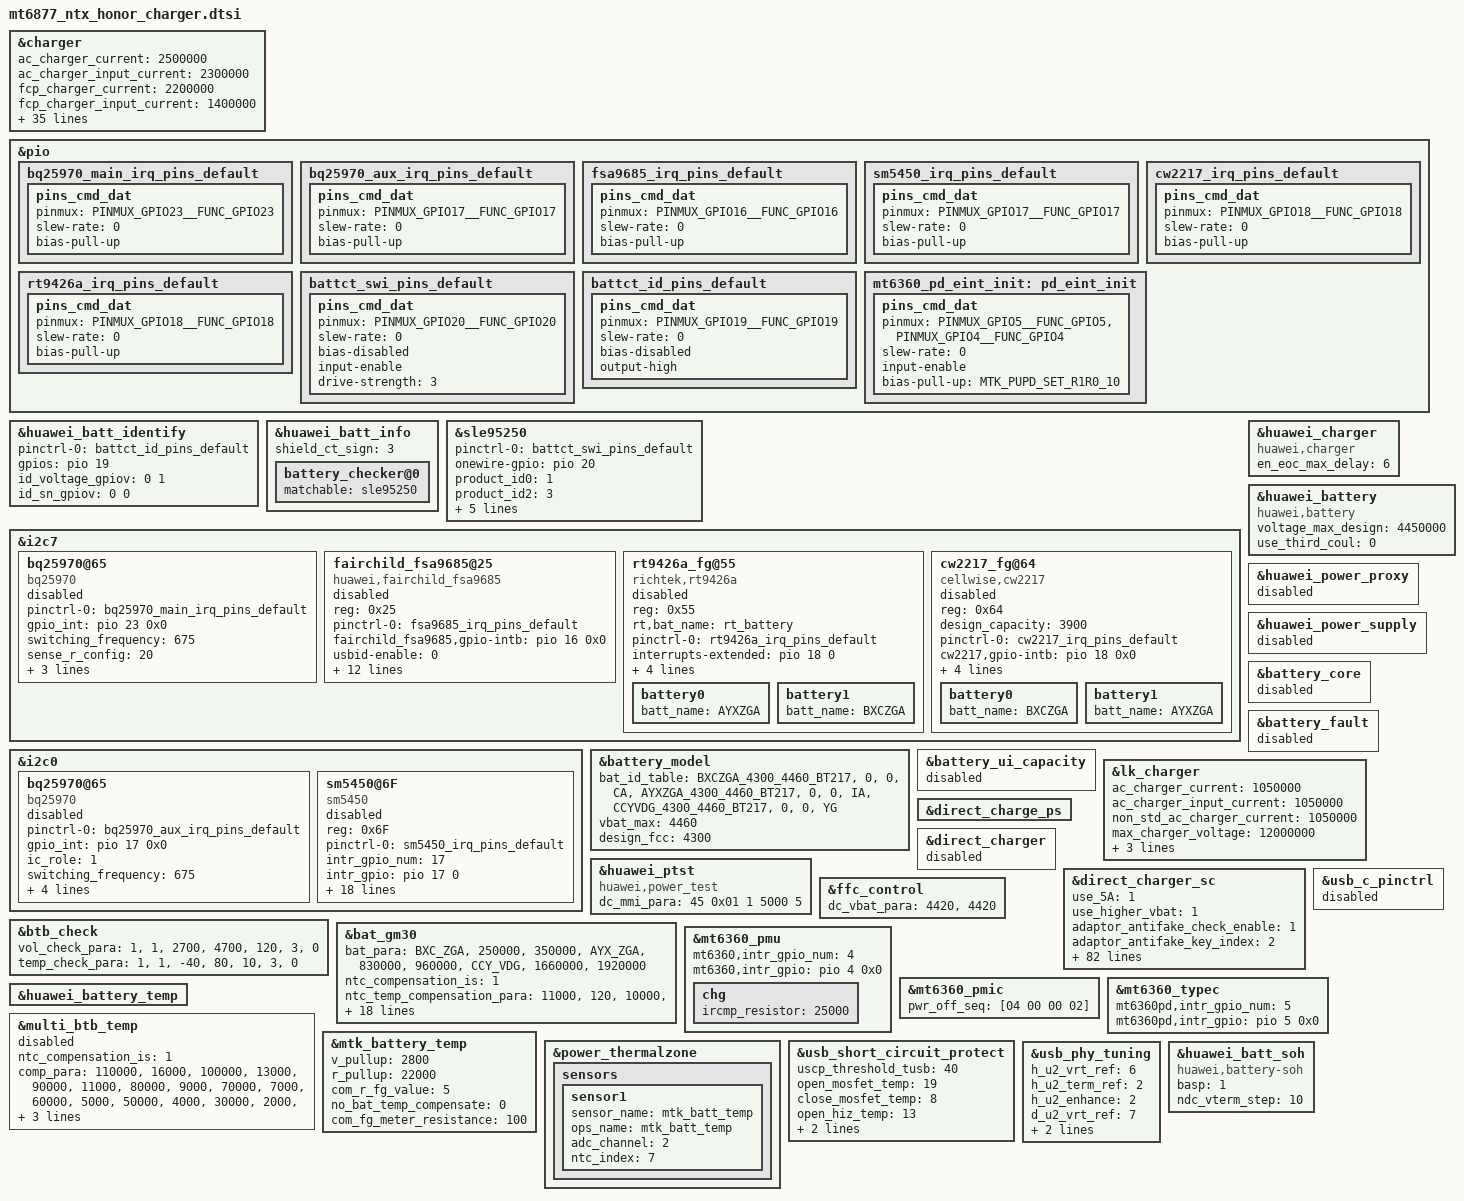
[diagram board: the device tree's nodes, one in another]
&charger {
	ac_charger_current = <2500000>;
	ac_charger_input_current = <2300000>;
	fcp_charger_current = <2200000>;
	fcp_charger_input_current = <1400000>;
	non_std_ac_charger_current = <1200000>;
	pd_vbus_upper_bound = <9000000>;
	max_charger_voltage = <12000000>;
	bc12_charger = <0>; /* mt6360 do bc12 */
	dpm_enable;
	battery_cv = <4450000>;
	sdp_battery_cv = <4430000>;
	iterm = <150000>;
	vbus_max_limit = <11500>;
	jeita_temp_above_t4_cv = <4100000>;
	jeita_temp_t3_to_t4_cv = <4100000>;
	jeita_temp_t2_to_t3_cv = <4450000>;
	jeita_temp_t1_to_t2_cv = <4430000>;
	jeita_temp_t0_to_t1_cv = <4430000>;
	jeita_temp_below_t0_cv = <4100000>;
	jeita_temp_t3_to_t4_cur = <1400000>;
	jeita_temp_t2_to_t3_cur = <2800000>;
	jeita_temp_t1_to_t2_cur = <1200000>;
	jeita_temp_t0_to_t1_cur = <420000>;
	dynamic_iterm_en;
	jeita_temp_t0_to_t1_iterm = <150000>;
	jeita_temp_t1_to_t2_iterm = <150000>;
	jeita_temp_t2_to_t3_iterm = <500000>;
	jeita_temp_t3_to_t4_iterm = <150000>;
	/* mode jeita param */
	support_over_volt = <1>;
	jeita_normal_temp_iterm = <500000>;
	jeita_normal_temp_cv = <4450000>;
	jeita_iin_therm_iterm = <150000>;
	jeita_iin_therm_cv = <4430000>;
	sdp_jeita_temp_t2_to_t3_cv = <4430000>;
	sdp_jeita_temp_t2_to_t3_iterm = <150000>;
	vdpm_buf_limit = <100>;
	vdpm_para =
			"-32767", "4000", "4300", "50",
			"4000", "4200", "4500", "50",
			"4200", "32767", "4600", "50";
	charge_full_design = <4300000>;
};

&pio {
	bq25970_main_irq_pins_default: bq25970_main_irq_pins_default {
		pins_cmd_dat {
			pinmux = <PINMUX_GPIO23__FUNC_GPIO23>;
			slew-rate = <0>;
			bias-pull-up;
		};
	};
	bq25970_aux_irq_pins_default: bq25970_aux_irq_pins_default {
		pins_cmd_dat {
			pinmux = <PINMUX_GPIO17__FUNC_GPIO17>;
			slew-rate = <0>;
			bias-pull-up;
		};
	};
	fsa9685_irq_pins_default: fsa9685_irq_pins_default {
		pins_cmd_dat {
			pinmux = <PINMUX_GPIO16__FUNC_GPIO16>;
			slew-rate = <0>;
			bias-pull-up;
		};
	};

	sm5450_irq_pins_default: sm5450_irq_pins_default {
		pins_cmd_dat {
			pinmux = <PINMUX_GPIO17__FUNC_GPIO17>;
			slew-rate = <0>;
			bias-pull-up;
		};
	};
	cw2217_irq_pins_default: cw2217_irq_pins_default {
		pins_cmd_dat {
			pinmux = <PINMUX_GPIO18__FUNC_GPIO18>;
			slew-rate = <0>;
			bias-pull-up;
		};
	};
	rt9426a_irq_pins_default: rt9426a_irq_pins_default {
		pins_cmd_dat {
			pinmux = <PINMUX_GPIO18__FUNC_GPIO18>;
			slew-rate = <0>;
			bias-pull-up;
		};
	};
        battct_swi_pins_default: battct_swi_pins_default {
                pins_cmd_dat {
                        pinmux = <PINMUX_GPIO20__FUNC_GPIO20>;
                        slew-rate = <0>;
                        bias-disabled;
                        input-enable;
                        drive-strength = <3>;
                };
        };
        battct_id_pins_default: battct_id_pins_default {
                pins_cmd_dat {
                        pinmux = <PINMUX_GPIO19__FUNC_GPIO19>;
                        slew-rate = <0>;
                        bias-disabled;
                        output-high;
                };
        };
};

&huawei_batt_identify {
        pinctrl-names = "default";
        pinctrl-0 = <&battct_id_pins_default>;
        gpios = <&pio 19 0x0>;
        id_voltage_gpiov = <0 1>;
        id_sn_gpiov = <0 0>;
        status = "ok";
};

&huawei_batt_info {
        status = "ok";
        shield_ct_sign = <3>;
        battery_checker@0 {
                matchable = <&sle95250>;
                status = "ok";
        };
};

&sle95250 {
        pinctrl-names = "default";
        pinctrl-0 = <&battct_swi_pins_default>;
        onewire-gpio = <&pio 20 0x0>;
        product_id0 = <1>;
        product_id2 = <3>;
        gpio_sn_mode_val = <0>;
        dip_check = <0>;
        gpio_swi = <20>;
        gpio_id_mode = <19>;
        gpio_swi_drv = <3>;
        status = "ok";
};

&i2c7 {
	bq25970@65 {
		compatible = "bq25970";
		pinctrl-names = "default";
		pinctrl-0 = <&bq25970_main_irq_pins_default>;
		gpio_int = <&pio 23 0x0>;
		switching_frequency = <675>;
		sense_r_config = <20>;
		sense_r_actual = <10>;
		reg = <0x65>;
		ibus_ocp_th = <4250>;
		status = "disabled";
	};

	fairchild_fsa9685@25 {
		compatible = "huawei,fairchild_fsa9685";
		reg = <0x25>;
		pinctrl-names = "default";
		pinctrl-0 = <&fsa9685_irq_pins_default>;
		fairchild_fsa9685,gpio-intb = <&pio 16 0x0>;
		usbid-enable = <0>;
		fcp_support = <1>;
		scp_support = <1>;
		mhl_detect_disable = <1>;
		power_by_5v = <1>;
		close_bc12 = <1>;
		need_other_bc12 = <0>;
		ignore_force_ac = <1>;
		/* for rt8979 */
		interrupt-names = "vbus_change", "device_change", "detach",
			"attach";
		/* auto_switch; */
		scp;
		dcd;
		dcd_timeout = <600>;  /* ms */
		intb_watchdog = <1000>;  /* ms */
		ovp_sel = <14500000>;  /* uV */
		status = "disabled";
	};

	rt9426a_fg@55 {
		compatible = "richtek,rt9426a";
		reg = <0x55>;
		status = "disabled";
		rt,bat_name = "rt_battery";
		pinctrl-names = "default";
		pinctrl-0 = <&rt9426a_irq_pins_default>;
		interrupts-extended = <&pio 18 0>;
		ntc_compensation_is = <1>;
		ntc_temp_compensation_para =
			"11000", "110",
			"10000", "100",
			"9000", "80",
			"8000", "60",
			"7000", "50",
			"6000", "40",
			"5000", "30",
			"3000", "20",
			"2000", "10";
		battery0{
			batt_name = "AYXZGA";
			#include "rt9426a_AYXZGA_4300mah_4V45_BT217.dtsi"
		};
		battery1{
			batt_name = "BXCZGA";
			#include "rt9426a_BXCZGA_4300mah_4V45_BT217.dtsi"
		};
	};
	cw2217_fg@64 {
		reg = <0x64>;
		compatible = "cellwise,cw2217";
		status = "disabled";
		design_capacity = <3900>;
		pinctrl-names = "default";
		pinctrl-0 = <&cw2217_irq_pins_default>;
		cw2217,gpio-intb = <&pio 18 0x0>;
		ntc_compensation_is = <1>;
		ntc_temp_compensation_para =
			"11000", "140",
			"10000", "120",
			"9000", "100",
			"8000", "80",
			"7000", "60",
			"6000", "50",
			"5000", "40",
			"3000", "20",
			"2000", "10";
		battery0{
			batt_name = "BXCZGA";
			#include "CW_BXCZGA_4460_4300mah_BT217.dtsi"
		};
		battery1{
			batt_name = "AYXZGA";
			#include "CW_AYXZGA_4460_4300mah_BT217.dtsi"
		};
	};
};
&i2c0 {
	bq25970@65 {
		compatible = "bq25970";
		pinctrl-names = "default";
		pinctrl-0 = <&bq25970_aux_irq_pins_default>;
		gpio_int = <&pio 17 0x0>;
		ic_role = <1>;
		switching_frequency = <675>;
		sense_r_config = <20>;
		sense_r_actual = <10>;
		reg = <0x65>;
		ibus_ocp_th = <4250>;
		status = "disabled";
	};

	sm5450@6F{
		compatible = "sm5450";
		reg = <0x6F>;
		pinctrl-names = "default";
		pinctrl-0 = <&sm5450_irq_pins_default>;
		intr_gpio_num = <17>;
		intr_gpio = <&pio 17 0>;
		ic_role = <1>;
		support_unbalanced_current_sc = <0>;
		adc_channel_vbat_sys = <14>;
		fcp_support = <1>;
		scp_support = <1>;
		lvc_ibat_regulator = <12200>;
		lvc_vbat_regulator = <4500>;
		lvc_vout_regulator = <4550>;
		lvc_ibus_regulator = <5600>;
		sc_ibat_regulator = <12200>;
		sc_vbat_regulator = <4500>;
		sc_vout_regulator = <4550>;
		sc_ibus_regulator = <5600>;
		lvc_vusb2vbus_drop_en = <1>;
		sc_vusb2vbus_drop_en = <1>;
		bat_comp = <0>;
		vclamp = <0>;
		r_coul_mohm = <2>;
		status = "disabled";
	};
};
&huawei_charger {
	compatible = "huawei,charger";
	en_eoc_max_delay = <6>;
	status = "okay";
};

&huawei_battery {
	compatible = "huawei,battery";
	voltage_max_design = <4450000>;
	use_third_coul = <0>;
	status = "okay";
};

&huawei_power_proxy  {
	status = "disabled";
};
&huawei_power_supply {
	status = "disabled";
};
&battery_core {
	status = "disabled";
};
&battery_fault {
	status = "disabled";
};
&battery_model {
	bat_id_table =
		"BXCZGA_4300_4460_BT217", "0", "0", "CA",
		"AYXZGA_4300_4460_BT217", "0", "0", "IA",
		"CCYVDG_4300_4460_BT217", "0", "0", "YG";
	vbat_max = <4460>;
	design_fcc = <4300>;
	status = "ok";
};
&battery_ui_capacity {
	status = "disabled";
};

&lk_charger{
	ac_charger_current = <1050000>;
	ac_charger_input_current = <1050000>;
	non_std_ac_charger_current = <1050000>;
	max_charger_voltage = <12000000>;
	is_power_path;
	poweron_charger_enable = <1>;

	/* charging anime */
	led_brightness = <200>;
};

&direct_charge_ps {
	status = "ok";
};

&direct_charger {
	status = "disabled";
};

&huawei_ptst {
	compatible = "huawei,power_test";
	dc_mmi_para = <45 0x01 1 5000 5>;
	status = "ok";
};

&direct_charger_sc {
	use_5A = <1>;
	use_higher_vbat = <1>;
	adaptor_antifake_check_enable = <1>;
	adaptor_antifake_key_index = <2>;
	dc_volt_ratio = <2>;
	max_adaptor_vset = <11000>;
	init_adapter_vset = <8800>;
	delta_err_10v2p25a = <150>;
	vol_err_th = <300>;
	adaptor_leakage_current_th = <300>;
	high_temp_hysteresis = <1>;
	gain_curr_10v2a = <300>;
	gain_curr_10v2p25a = <500>;
	init_delt_vset = <450>;
	vstep = <20>;
	max_dc_bat_vol = <4380>;
	max_current_for_none_standard_cable = <6000>;
	main_ic_ibus_limit_current_max = <4000>;
	aux_ic_ibus_limit_current_max = <2900>;
	ibus_limit_current_delta = <100>;
	dc_use_fg_get_battery_current = <1>;
	support_unbalanced_current_sc = <1>;
	support_basp_stage_volt_para = <1>;
	basp_first_cc_cycle_min = <30>;
	basp_first_cc_cycle_max = <100>;
	basp_first_cc_vterm_dec = <30>;
	basp_first_cc_vterm_asc = <20>;
	multi_ic_info_ibat_th = <8000>;
	product_max_pwr = <66000>;
	ui_max_pwr = <40000>;
	time_para =
                "120", "10000";
	volt_para =
		"4150", "8400", "6300",
		"4250", "6300", "5040",
		"4300", "5040", "4200",
		"4450", "4200", "2940",
		"4460", "2940", "1200";
	volt_para1 =
		"4180", "12200", "10000",
		"4250", "10000", "8400",
		"4300", "8400", "6300",
		"4380", "6300", "5040",
		"4450", "5040", "4200",
		"4460", "4200", "1200";
	bat_para =
		"ZGA", "10", "20", "volt_para",
		"ZGA", "20", "45", "volt_para1",
		"VDG", "10", "20", "volt_para",
		"VDG", "20", "45", "volt_para1",
		"default", "10", "20", "volt_para",
		"default", "20", "45", "volt_para1";
	second_resist_para =
		"0", "250", "0",
		"250", "450", "8000";
	vbat_error =
		"3", "120", "2", "-1",
		"3", "80", "1", "8000";
	current_ratio =
		"3", "6", "16", "2", "-1",
		"3", "9", "13", "1", "8000",
		"0", "9", "13", "0", "0";
	current_ratio1 =
		"3", "10", "20", "2", "-1",
		"3", "11", "15", "1", "8000",
		"0", "11", "15", "0", "0";
	current_ratio2 =
		"3", "10", "20", "2", "-1",
		"3", "13", "17", "1", "8000",
		"0", "13", "17", "0", "0";
	current_ratio3 =
		"3", "10", "20", "2", "-1",
		"3", "11", "15", "1", "8000",
		"0", "11", "15", "0", "0";
	current_ratio4 =
		"3", "10", "20", "2", "-1",
		"3", "14", "18", "1", "8000",
		"0", "14", "18", "0", "0";
	muti_ic_comb_ratio_para =
		"rt9759", "sc8545_aux", "current_ratio1",
		"rt9759", "sm5450_aux", "current_ratio2",
		"bq25970", "sc8545_aux", "current_ratio3",
		"bq25970", "sm5450_aux", "current_ratio4";
	adapter_max_power_time_para =
		"3", "600", "6000",
		"4", "1200", "3000",
		"5", "600", "6000",
		"6", "600", "6000",
		"7", "600", "6000",
		"8", "600", "6000",
		"9", "1200", "3000",
		"10", "1200", "3000",
		"12", "600", "6000",
		"13", "600", "6000",
		"14", "600", "6000",
		"15", "1200", "3000";
	vstep_para =
			"2000", "80";
	compensate_r = <0>;
	cc_cable_detect_enable = <1>;
	cc_unsafe_sc_enable = <0>;
	full_path_res_max = <500>;
	scp_work_on_charger = <1>;
	standard_cable_full_path_res_max = <500>;
	first_cc_stage_timer_in_min = <14>;
	stage_need_to_jump = "-1";
	is_show_ico_first = <1>;
	is_send_cable_type = <0>;
	support_multi_ic = <1>;
	vbat_comp_para = <13 0 45 13 1 45 16 0 35 16 1 35>;
	10v4a_cur_para =
		"-32767", "11000", "4000";
	rt_test_para =
		/* first:sc second:mainsc third:auxsc */
		"1500", "105",
		"1500", "105",
		"1500", "105";
	temp_para =
		"-32767", "10", "0",
		"10", "46", "12500",
		"46", "32767", "0";
	resist_para =
		"0", "300", "6000",
		"300", "500", "5000";
	std_resist_para =
		"0", "300", "12200",
		"300", "500", "5000";
	10v2p25a_cur_para =
		"-32767", "5500",  "2000",
		"5500",   "9000",  "2500",
		"9000",   "10000", "2250",
		"10000",  "10500", "2000",
		"10500",  "32767", "1500";
	status = "ok";
};

&ffc_control {
	status = "ok";
	dc_vbat_para =
		"4420", "4420";
};

&btb_check {
	vol_check_para = "1", "1", "2700", "4700", "120", "3", "0";
	temp_check_para = "1", "1", "-40", "80", "10", "3", "0";
	status = "ok";
};

&bat_gm30 {
	bat_para =
		"BXC_ZGA", "250000", "350000",
		"AYX_ZGA", "830000", "960000",
		"CCY_VDG", "1660000", "1920000";
	ntc_compensation_is = <1>;
	ntc_temp_compensation_para =
		"11000", "120",
		"10000", "100",
		"9000", "70",
		"8000", "60",
		"7000", "40",
		"6000", "30",
		"5000", "20",
		"3000", "10",
		"2000", "0";
	min_fcc = <2838000>;
	max_fcc = <4300000>;
	dlpt_optimization;
	soc_algo_factor = <15>;
	CAR_TUNE_VALUE = <(500)>;
	ACTIVE_TABLE = <(0)>;
	MULTI_BATTERY = <0>;
	COM_FG_METER_RESISTANCE = <(0)>;
	COM_R_FG_VALUE = <(0)>;
	SLEEP_CURRENT_AVG = <500>;
	g_FG_PSEUDO100_T0 = <(97)>;
	g_FG_PSEUDO100_T1 = <(97)>;
	g_FG_PSEUDO100_T2 = <(97)>;
	g_FG_PSEUDO100_T3 = <(97)>;
	g_FG_PSEUDO100_T4 = <(97)>;
	low_capacity_volt_check_en = <0>;
	#include "AYXZGA_4v46_4300mah_BT217.dtsi"
	#include "BXCZGA_4v46_4300mah_BT217.dtsi"
	#include "CCYVDG_4v46_4300mah_BT217.dtsi"
};

&usb_c_pinctrl {
	status = "disabled";
};

&mt6360_pmu {
	mt6360,intr_gpio_num = <4>; /* direct defined GPIO num */
	mt6360,intr_gpio = <&pio 4 0x0>;
	chg {
		ircmp_resistor = <25000>;
	};
};

&mt6360_pmic {
	pwr_off_seq = [04 00 00 02];
};

&mt6360_typec {
	mt6360pd,intr_gpio_num = <5>; /* direct defined GPIO num */
	mt6360pd,intr_gpio = <&pio 5 0x0>;
};

&pio {
	mt6360_pd_eint_init: pd_eint_init {
		pins_cmd_dat {
			pinmux = <PINMUX_GPIO5__FUNC_GPIO5>,<PINMUX_GPIO4__FUNC_GPIO4>;
			slew-rate = <0>;
			input-enable;
			bias-pull-up = <MTK_PUPD_SET_R1R0_10>;
		};
	};
};

&huawei_battery_temp {
	status = "ok";
};

&multi_btb_temp {
	status = "disabled";
	ntc_compensation_is = <1>;
	comp_para =
		"110000", "16000",
		"100000", "13000",
		"90000", "11000",
		"80000", "9000",
		"70000", "7000",
		"60000", "5000",
		"50000", "4000",
		"30000", "2000",
		"20000", "1000";
	sensor-names =
		"mtk_batt_temp", "comp_para",
		"mtk_batt_temp", "comp_para";
};

&mtk_battery_temp {
	v_pullup = <2800>;
	r_pullup = <22000>;
	com_r_fg_value = <5>;
	no_bat_temp_compensate = <0>;
	com_fg_meter_resistance = <100>;
	status = "ok";
};

&power_thermalzone {
	status = "ok";
	sensors {
		sensor1 {
			sensor_name = "mtk_batt_temp";
			ops_name = "mtk_batt_temp";
			adc_channel = <2>;
			ntc_index = <7>;
		};
	};
};

&usb_short_circuit_protect {
	status = "ok";
	uscp_threshold_tusb = <40>;
	open_mosfet_temp = <19>;
	close_mosfet_temp = <8>;
	open_hiz_temp = <13>;
	interval_switch_temp = <7>;
	gpio_uscp = <&pio 111 0>;
};

&usb_phy_tuning {
		h_u2_vrt_ref = <6>;
		h_u2_term_ref = <2>;
		h_u2_enhance = <2>;
		d_u2_vrt_ref = <7>;
		d_u2_term_ref = <2>;
		d_u2_enhance = <3>;
		status = "ok";
};

&huawei_batt_soh {
	compatible = "huawei,battery-soh";
	basp = <1>;
	ndc_vterm_step = <10>;
	status = "ok";
};
